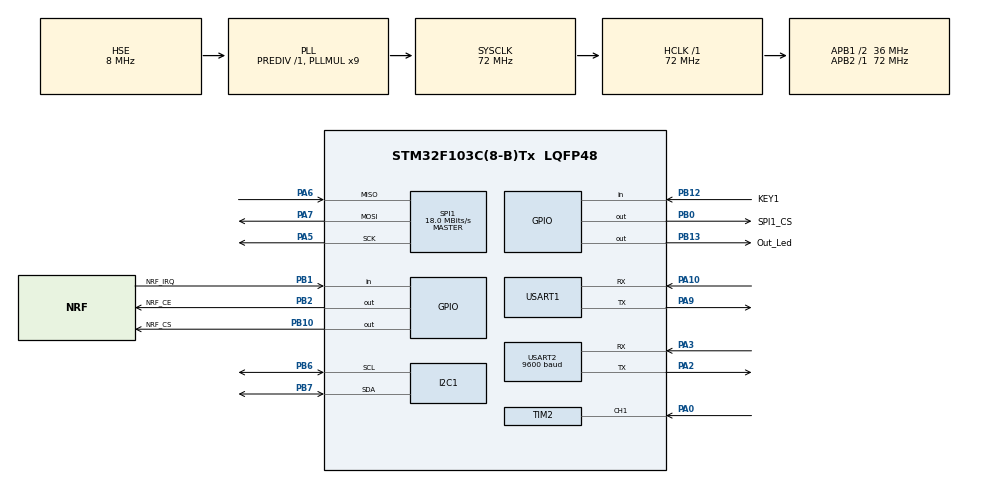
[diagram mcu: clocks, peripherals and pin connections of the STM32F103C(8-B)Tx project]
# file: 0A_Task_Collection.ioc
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Dma.Request0=USART1_TX
Dma.Request1=USART2_RX
Dma.Request2=USART2_TX
Dma.Request3=USART1_RX
Dma.USART1_RX.3.Direction=DMA_PERIPH_TO_MEMORY
Dma.USART1_RX.3.Instance=DMA1_Channel5
Dma.USART1_RX.3.MemDataAlignment=DMA_MDATAALIGN_BYTE
Dma.USART1_RX.3.MemInc=DMA_MINC_ENABLE
Dma.USART1_RX.3.Mode=DMA_NORMAL
Dma.USART1_RX.3.PeriphDataAlignment=DMA_PDATAALIGN_BYTE
Dma.USART1_RX.3.PeriphInc=DMA_PINC_DISABLE
Dma.USART1_RX.3.Priority=DMA_PRIORITY_LOW
Dma.USART1_TX.0.Direction=DMA_MEMORY_TO_PERIPH
Dma.USART1_TX.0.Instance=DMA1_Channel4
Dma.USART1_TX.0.MemDataAlignment=DMA_MDATAALIGN_BYTE
Dma.USART1_TX.0.MemInc=DMA_MINC_ENABLE
Dma.USART1_TX.0.Mode=DMA_NORMAL
Dma.USART1_TX.0.PeriphDataAlignment=DMA_PDATAALIGN_BYTE
Dma.USART1_TX.0.PeriphInc=DMA_PINC_DISABLE
Dma.USART1_TX.0.Priority=DMA_PRIORITY_LOW
Dma.USART2_RX.1.Direction=DMA_PERIPH_TO_MEMORY
Dma.USART2_RX.1.Instance=DMA1_Channel6
Dma.USART2_RX.1.MemDataAlignment=DMA_MDATAALIGN_BYTE
Dma.USART2_RX.1.MemInc=DMA_MINC_ENABLE
Dma.USART2_RX.1.Mode=DMA_NORMAL
Dma.USART2_RX.1.PeriphDataAlignment=DMA_PDATAALIGN_BYTE
Dma.USART2_RX.1.PeriphInc=DMA_PINC_DISABLE
Dma.USART2_RX.1.Priority=DMA_PRIORITY_LOW
Dma.USART2_TX.2.Direction=DMA_MEMORY_TO_PERIPH
Dma.USART2_TX.2.Instance=DMA1_Channel7
Dma.USART2_TX.2.MemDataAlignment=DMA_MDATAALIGN_BYTE
Dma.USART2_TX.2.MemInc=DMA_MINC_ENABLE
Dma.USART2_TX.2.Mode=DMA_NORMAL
Dma.USART2_TX.2.PeriphDataAlignment=DMA_PDATAALIGN_BYTE
Dma.USART2_TX.2.PeriphInc=DMA_PINC_DISABLE
Dma.USART2_TX.2.Priority=DMA_PRIORITY_LOW
Mcu.Family=STM32F1
Mcu.Name=STM32F103C(8-B)Tx
Mcu.Package=LQFP48
NVIC.DMA1_Channel4_IRQn=true\:0\:0\:false\:false\:true\:false\:true\:true
NVIC.DMA1_Channel5_IRQn=true\:0\:0\:false\:false\:true\:false\:true\:true
NVIC.DMA1_Channel6_IRQn=true\:0\:0\:false\:false\:true\:false\:true\:true
NVIC.DMA1_Channel7_IRQn=true\:0\:0\:false\:false\:true\:false\:true\:true
NVIC.PriorityGroup=NVIC_PRIORITYGROUP_4
NVIC.TIM2_IRQn=true\:0\:0\:false\:false\:true\:true\:true\:true
NVIC.USART1_IRQn=true\:0\:0\:false\:false\:true\:true\:true\:true
NVIC.USART2_IRQn=true\:0\:0\:false\:false\:true\:true\:true\:true
PA0-WKUP.Signal=S_TIM2_CH1_ETR
PA10.Mode=Asynchronous
PA10.Signal=USART1_RX
PA13.Mode=Serial_Wire
PA13.Signal=SYS_JTMS-SWDIO
PA14.Mode=Serial_Wire
PA14.Signal=SYS_JTCK-SWCLK
PA2.Mode=Asynchronous
PA2.Signal=USART2_TX
PA3.Mode=Asynchronous
PA3.Signal=USART2_RX
PA5.Mode=Full_Duplex_Master
PA5.Signal=SPI1_SCK
PA6.Mode=Full_Duplex_Master
PA6.Signal=SPI1_MISO
PA7.Mode=Full_Duplex_Master
PA7.Signal=SPI1_MOSI
PA9.Mode=Asynchronous
PA9.Signal=USART1_TX
PB0.GPIO_Label=SPI1_CS
PB0.GPIO_PuPd=GPIO_NOPULL
PB0.GPIO_Speed=GPIO_SPEED_FREQ_HIGH
PB0.Signal=GPIO_Output
PB1.GPIO_Label=NRF_IRQ
PB1.GPIO_PuPd=GPIO_PULLUP
PB1.Signal=GPIO_Input
PB10.GPIO_Label=NRF_CS
PB10.Signal=GPIO_Output
PB12.GPIO_Label=KEY1
PB12.Signal=GPIO_Input
PB13.GPIO_Label=Out_Led
PB13.GPIO_PuPd=GPIO_PULLDOWN
PB13.Signal=GPIO_Output
PB2.GPIO_Label=NRF_CE
PB2.PinState=GPIO_PIN_SET
PB2.Signal=GPIO_Output
PB6.Mode=I2C
PB6.Signal=I2C1_SCL
PB7.Mode=I2C
PB7.Signal=I2C1_SDA
PD0-OSC_IN.Mode=HSE-External-Oscillator
PD0-OSC_IN.Signal=RCC_OSC_IN
PD1-OSC_OUT.Mode=HSE-External-Oscillator
PD1-OSC_OUT.Signal=RCC_OSC_OUT
ProjectManager.HeapSize=0x200
ProjectManager.StackSize=0x400
ProjectManager.TargetToolchain=EWARM V8.32
RCC.ADCPresc=RCC_ADCPCLK2_DIV6
RCC.AHBFreq_Value=72000000
RCC.APB1CLKDivider=RCC_HCLK_DIV2
RCC.APB1Freq_Value=36000000
RCC.APB1TimFreq_Value=72000000
RCC.APB2Freq_Value=72000000
RCC.APB2TimFreq_Value=72000000
RCC.HCLKFreq_Value=72000000
RCC.PLLMUL=RCC_PLL_MUL9
RCC.PLLSourceVirtual=RCC_PLLSOURCE_HSE
RCC.SYSCLKFreq_VALUE=72000000
RCC.SYSCLKSource=RCC_SYSCLKSOURCE_PLLCLK
RCC.USBFreq_Value=72000000
SH.S_TIM2_CH1_ETR.0=TIM2_CH1,Input_Capture1_from_TI1
SPI1.BaudRatePrescaler=SPI_BAUDRATEPRESCALER_4
SPI1.CLKPhase=SPI_PHASE_2EDGE
SPI1.CalculateBaudRate=18.0 MBits/s
SPI1.Direction=SPI_DIRECTION_2LINES
SPI1.Mode=SPI_MODE_MASTER
SPI1.VirtualType=VM_MASTER
TIM2.Channel-Input_Capture1_from_TI1=TIM_CHANNEL_1
TIM2.Period=1000-1
TIM2.Prescaler=72-1
USART1.VirtualMode=VM_ASYNC
USART2.BaudRate=9600
USART2.VirtualMode=VM_ASYNC
VP_TIM2_VS_ClockSourceINT.Mode=Internal
board=custom

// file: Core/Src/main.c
/* USER CODE BEGIN Header */

/**

  ******************************************************************************

  * @file           : main.c

  * @brief          : Main program body

  ******************************************************************************

  * @attention

  *

  * Copyright (c) 2023 STMicroelectronics.

  * All rights reserved.

  *

  * This software is licensed under terms that can be found in the LICENSE file

  * in the root directory of this software component.

  * If no LICENSE file comes with this software, it is provided AS-IS.

  *

  ******************************************************************************

  */

/* USER CODE END Header */

#include "main.h"

#include "dma.h"

#include "i2c.h"

#include "spi.h"

#include "tim.h"

#include "usart.h"

#include "gpio.h"

/* USER CODE BEGIN Includes */

#include "bsp.h"

/* USER CODE END Includes */

void SystemClock_Config(void);

int main(void)

{

  /* MCU Configuration--------------------------------------------------------*/

  /* Reset of all peripherals, Initializes the Flash interface and the Systick. */

  HAL_Init();

  /* Configure the system clock */

  SystemClock_Config();

  /* Initialize all configured peripherals */

  MX_GPIO_Init();

  MX_DMA_Init();

  MX_USART1_UART_Init();

  MX_TIM2_Init();

  MX_I2C1_Init();

  MX_USART2_UART_Init();

  MX_SPI1_Init();

  /* USER CODE BEGIN 2 */

  systickConfigure();

//  // 初始化

//	//W25QXX_Init();

//	// 芯片flash大小

//	uint32_t FLASH_SIZE = 8*1024*1024;	// FLASH 大小8M字节

//

//	printf("------------- 读取芯片ID实验 --------------- \r\n");

//	uint16_t Deceive_ID;

//

//	Deceive_ID = W25QXX_ReadID();

//	if (Deceive_ID == 0)

//	{

//		printf("Read Deceive_ID fail \r\n");

//	} else {

//		printf("Deceive_ID is %X \r\n", Deceive_ID); // 显示芯片ID

//	}

//

//	printf("------------- 读写 字节实验 --------------- \r\n");

//	uint8_t string[] = {"HAOZI TEST"};

//	uint8_t getStringBuf[sizeof(string)] = {"&&&&&&&&&&"};		// 初始值

//

//	W25QXX_Write(string, 0, sizeof(string));

//	W25QXX_Read(getStringBuf, 0, sizeof(string));

//	if (getStringBuf[0] == '&')

//	{

//		printf("Read string fail \r\n");

//	} else {

//		printf("Read string is: %s \r\n", getStringBuf);

//	}

//

//	printf("------------- 读写 浮点数实验 --------------- \r\n");

//	// 浮点数 读写测试

//	union float_union{

//		float float_num;			// 浮点数占4个字节

//		double double_num;			// 双精度浮点数占8个字节

//		uint8_t buf[8];				// 定义 8个字节 的空间

//	};

//	union float_union write_float_data;	// 用来写

//	union float_union read_float_data;	// 用来读

//

//	// 先测试第一个 浮点数

//	write_float_data.float_num = 3.1415f;

//	read_float_data.float_num = 0;

//	W25QXX_Write(write_float_data.buf, 20, 4);

//	W25QXX_Read(read_float_data.buf, 20, 4);

//	if(read_float_data.float_num == 0)

//	{

//		printf("Read float fail \r\n");

//	} else {

//		printf("Read float data is %f \r\n", read_float_data.float_num);

//	}

//	// 再测试第二个 双精度浮点数

//	write_float_data.double_num = 3.1415;

//	read_float_data.double_num = 0;

//

//	W25QXX_Write(write_float_data.buf, 20, 8);

//	W25QXX_Read(read_float_data.buf, 20, 8);

//	if(read_float_data.float_num == 0)

//	{

//		printf("Read double fail \r\n");

//	} else {

//		printf("Read double data is %.15f \r\n", read_float_data.double_num);

//	}

  /* USER CODE END 2 */

  /* Infinite loop */

  while (1)
  {

    /* USER CODE BEGIN 3 */

    //loop();

  }

  /* USER CODE END 3 */

}

void SystemClock_Config(void)

{

  RCC_OscInitTypeDef RCC_OscInitStruct = {0};

  RCC_ClkInitTypeDef RCC_ClkInitStruct = {0};

  /** Initializes the RCC Oscillators according to the specified parameters

  * in the RCC_OscInitTypeDef structure.

  */

  RCC_OscInitStruct.OscillatorType = RCC_OSCILLATORTYPE_HSE;

  RCC_OscInitStruct.HSEState = RCC_HSE_ON;

  RCC_OscInitStruct.HSEPredivValue = RCC_HSE_PREDIV_DIV1;

  RCC_OscInitStruct.HSIState = RCC_HSI_ON;

  RCC_OscInitStruct.PLL.PLLState = RCC_PLL_ON;

  RCC_OscInitStruct.PLL.PLLSource = RCC_PLLSOURCE_HSE;

  RCC_OscInitStruct.PLL.PLLMUL = RCC_PLL_MUL9;

  if (HAL_RCC_OscConfig(&RCC_OscInitStruct) != HAL_OK)

  {

    Error_Handler();

  }

  /** Initializes the CPU, AHB and APB buses clocks

  */

  RCC_ClkInitStruct.ClockType = RCC_CLOCKTYPE_HCLK|RCC_CLOCKTYPE_SYSCLK

                              |RCC_CLOCKTYPE_PCLK1|RCC_CLOCKTYPE_PCLK2;

  RCC_ClkInitStruct.SYSCLKSource = RCC_SYSCLKSOURCE_PLLCLK;

  RCC_ClkInitStruct.AHBCLKDivider = RCC_SYSCLK_DIV1;

  RCC_ClkInitStruct.APB1CLKDivider = RCC_HCLK_DIV2;

  RCC_ClkInitStruct.APB2CLKDivider = RCC_HCLK_DIV1;

  if (HAL_RCC_ClockConfig(&RCC_ClkInitStruct, FLASH_LATENCY_2) != HAL_OK)

  {

    Error_Handler();

  }

}

void Error_Handler(void)

{

  __disable_irq();
  while (1)
  {
  }

}
